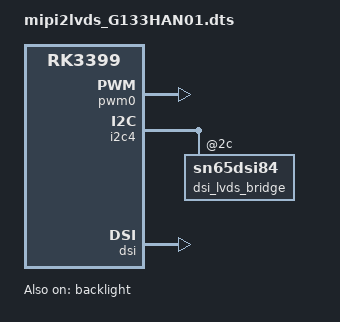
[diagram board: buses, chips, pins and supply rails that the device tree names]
/dts-v1/;
/plugin/;
/ {
	compatible = "rockchip,rk3399-excavator-linux", "rockchip,rk3399";

	fragment@0 {
		target = <&pwm0>;
		__overlay__ {
			status = "okay";
		};
	};
	fragment@1 {
		target = <&backlight>;
		__overlay__ {
			status = "okay";
			pwms = <&pwm0 0 2000000 0>;
                        disable_delay = <15>;
                        power-sequence-reverse;
                        minimal-brightness-level = <15>;
		};
	};
	fragment@2 {
		target = <&i2c4>;
		__overlay__ {
			status = "okay";
			dsi_lvds_bridge: sn65dsi84@2c {
				status = "okay";
				lvds-clk-rate = <67450000>;
				lvds-format = <1>;
				lvds-bpp = <24>;
				lvds-width-mm = <293>;
				lvds-height-mm = <165>;
				sync_delay = <33>;
				dual-link;

				t1=<0>;
				t2=<250>;
				t3=<100>;
				t4=<100>;
				t5=<20>;
				t6=<0>;
				t7=<1000>;

				bpc=<8>;
				bus-format = <0x100a>;
				dsi,flags = <0x3>;
				dsi,format = <0>;
				dsi-lanes = <4>;

				display-timings {
					lvds {
						clock-frequency = <134900000>;
						hactive = <1920>;
						vactive = <1080>;
						hfront-porch = <40>;
						hback-porch = <40>;
						hsync-len = <46>;
						vfront-porch = <4>;
						vsync-len = <4>;
						vback-porch = <4>;
						hsync-active = <0>;
						vsync-active = <0>;
						de-active = <1>;
						pixelclk-active = <0>;
					};
				};
			};
		};
	};
	fragment@3 {
		target = <&dsi>;
		__overlay__ {
			status = "okay";
			mipi_panel: mipi-panel {
				status = "disabled";
			};
		};
	};
        fragment@4 {
		target = <&pinctrl>;
		__overlay__ {
			gpio_init_config {
				gpio_init: gpio-init {
                                           rockchip,pins =
                                                <1 8 0  &pcfg_pull_none>;
				};
			};
		};
	};

};
